# INTRCONN_SOCKET_CM2 register map
Vendor: Texas Instruments
Peripheral module from a debugger description file (folder omap4430).
Registers are 32-bit, read-only, no defined reset value unless marked. A register's access mark holds for its fields unless they carry their own. Offsets are as the file gives them; lines under a group give offsets from that group; [hi:lo] are bit positions; {n}, {i} and the like mark numbered series; 'fields as' and 'values as' point back to an identical list; <NAME> marks a mode.

## INTRCONN_SOCKET_CM2
0x00 REVISION_CM2 — This register contains the IP revision code for the CM2 part of the PRCM
  [31:0] REVISION — Revision Number
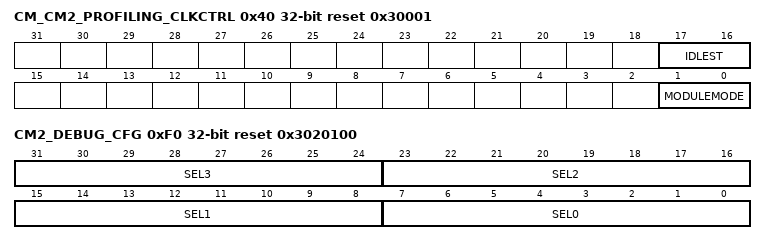
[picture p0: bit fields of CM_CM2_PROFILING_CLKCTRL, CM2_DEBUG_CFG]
0x40 CM_CM2_PROFILING_CLKCTRL access per field reset 0x30001 — This register manages the CM2_PROFILING clocks. [warm reset insensitive]
  [17:16] IDLEST ro — Module idle status
    0=IDLEST_0_r (Module is fully functional); 1=IDLEST_1_r (Module is performing transition: wakeup, or sleep, or sleep abortion); 2=IDLEST_2_r (Module is in Idle); 3=IDLEST_3_r (Module is disabled)
  [1:0] MODULEMODE rw — Control the way mandatory clocks are managed.
    0=Module is disabled by software. INTRCONN configuration port is not accessible.; 1=Module is managed automatically by hardware along with L3INSTR domain; 2=MODULEMODE_2_r (Reserved); 3=MODULEMODE_3_r (Reserved)
0xF0 CM2_DEBUG_CFG rw reset 0x3020100 — This register is used to configure the CM2's 32-bit debug output. There is one 7-bit source select field for selecting from a shared set of 8-bit internal signal blocks per byte. [warm reset insensitive]
  [8n+7:8n] SEL{n} (n=0..3) — Internal signal block select for debug word byte-{n}
